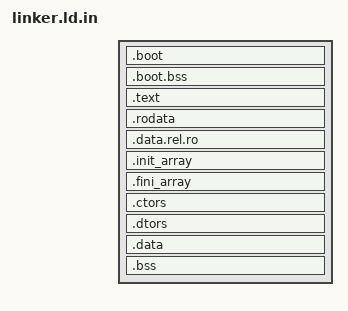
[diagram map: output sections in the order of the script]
/*
 * config/linker.ld.in
 *
 * Preprocessed into build/linker.ld. The addresses come from config/layout.h, which the early
 * boot assembly includes as well, so the two cannot drift apart.
 */

#include "config/layout.h"

ENTRY(_start32)

KERNEL_LMA = DOOM_OS_KERNEL_LMA;
KERNEL_VMA = DOOM_OS_KERNEL_VMA;

/*
 * Both sides take this from config/layout.h now, so they agree by construction - but a stale
 * build/linker.ld would not, and a kernel linked at one address and mapped at another shows up
 * as a triple fault on the jump to the higher half and nothing else. Cheap to keep checking.
 */
ASSERT(ASM_KERNEL_VMA == KERNEL_VMA,
       "KERNEL_VMA disagrees between config/linker.ld and kernel/boot/longmode.S")

PF_X = 0x1;
PF_W = 0x2;
PF_R = 0x4;

PHDRS
{
    /*
     * FILEHDR PHDRS makes the first PT_LOAD segment include the ELF header
     * and program headers. This prevents the first loadable section from
     * being pushed too far into the file.
     */
    boot   PT_LOAD FILEHDR PHDRS FLAGS(PF_R | PF_W | PF_X);
    text   PT_LOAD FLAGS(PF_R | PF_X);
    rodata PT_LOAD FLAGS(PF_R);
    data   PT_LOAD FLAGS(PF_R | PF_W);
}

SECTIONS
{
    /*
     * Start after the ELF/program headers inside the first PT_LOAD segment.
     * The Multiboot2 header below must still appear within the first 32 KiB
     * of the final kernel image.
     */
    . = KERNEL_LMA + SIZEOF_HEADERS;

    boot_start = .;

    .boot ALIGN(8) : AT(ADDR(.boot))
    {
        . = ALIGN(8);

        /*
         * GRUB requires the full Multiboot2 header to be 8-byte aligned and
         * fully contained within the first 32 KiB of the image.
         */
        KEEP(*(.multiboot2_header))
        KEEP(*(.multiboot2))
        KEEP(*(.multiboot))

        *(.boot.text .boot.text.*)
        *(.boot.rodata .boot.rodata.*)
        *(.boot.data .boot.data.*)
    } :boot

    .boot.bss ALIGN(4K) (NOLOAD) : AT(ADDR(.boot.bss))
    {
        boot_bss_start = .;
        *(.boot.bss .boot.bss.*)
        boot_bss_end = .;
    } :boot

    . = ALIGN(4K);
    boot_end = .;

    . = KERNEL_VMA + boot_end;

    kernel_start = .;

    .text ALIGN(4K) : AT(ADDR(.text) - KERNEL_VMA)
    {
        __text_start = .;
        *(.text .text.*)
        *(.gnu.linkonce.t.*)
        __text_end = .;
    } :text

    .rodata ALIGN(4K) : AT(ADDR(.rodata) - KERNEL_VMA)
    {
        __rodata_start = .;
        *(.rodata .rodata.*)
        *(.gnu.linkonce.r.*)
        __rodata_end = .;
    } :rodata

    /*
     * Keep these writable for now.
     * They are often logically read-only after relocation/init,
     * but for a freestanding kernel bring-up it is safer not to
     * make them R-only yet.
     */
    .data.rel.ro ALIGN(4K) : AT(ADDR(.data.rel.ro) - KERNEL_VMA)
    {
        __data_rel_ro_start = .;
        *(.data.rel.ro .data.rel.ro.*)
        *(.data.rel.ro.local .data.rel.ro.local.*)
        __data_rel_ro_end = .;
    } :data

    .init_array ALIGN(8) : AT(ADDR(.init_array) - KERNEL_VMA)
    {
        __init_array_start = .;
        KEEP(*(SORT_BY_INIT_PRIORITY(.init_array.*)))
        KEEP(*(.init_array))
        __init_array_end = .;
    } :data

    .fini_array ALIGN(8) : AT(ADDR(.fini_array) - KERNEL_VMA)
    {
        __fini_array_start = .;
        KEEP(*(SORT_BY_INIT_PRIORITY(.fini_array.*)))
        KEEP(*(.fini_array))
        __fini_array_end = .;
    } :data

    /* GCC emits global constructors into either .init_array or the legacy .ctors, and which one
       is decided when GCC itself is configured, not by any flag we can pass here. A cross GCC
       built --without-headers cannot run the configure probe that selects .init_array, so it
       falls back to .ctors unless it was built --enable-initfini-array.
       kernel/runtime/init.cpp walks .init_array. Collecting .ctors here and asserting it empty is what
       stops a toolchain of the wrong kind from silently dropping every constructor in the image
       into an orphan section nothing ever calls. */
    .ctors ALIGN(8) : AT(ADDR(.ctors) - KERNEL_VMA)
    {
        __ctors_start = .;
        KEEP(*(SORT_BY_NAME(.ctors.*)))
        KEEP(*(.ctors))
        __ctors_end = .;
    } :data

    .dtors ALIGN(8) : AT(ADDR(.dtors) - KERNEL_VMA)
    {
        __dtors_start = .;
        KEEP(*(SORT_BY_NAME(.dtors.*)))
        KEEP(*(.dtors))
        __dtors_end = .;
    } :data

    ASSERT(__ctors_end == __ctors_start,
           "This toolchain emits .ctors instead of .init_array, so global constructors would \
never run. Rebuild the toolchain image with --enable-initfini-array.")

    ASSERT(__dtors_end == __dtors_start,
           "This toolchain emits .dtors instead of .fini_array.")

    .data ALIGN(4K) : AT(ADDR(.data) - KERNEL_VMA)
    {
        __data_start = .;
        *(.data .data.*)
        *(.gnu.linkonce.d.*)

        *(.got .got.*)
        *(.got.plt .got.plt.*)
        __data_end = .;
    } :data

    .bss ALIGN(4K) : AT(ADDR(.bss) - KERNEL_VMA)
    {
        __bss_start = .;

        *(COMMON)
        *(.bss .bss.*)
        *(.gnu.linkonce.b.*)

        __bss_end = .;
    } :data

    . = ALIGN(4K);
    kernel_end = .;

    kernel_physical_start = kernel_start - KERNEL_VMA;
    kernel_physical_end = kernel_end - KERNEL_VMA;

    /*
     * The early page tables cover DOOM_OS_EARLY_MAP_SIZE from zero and from KERNEL_VMA. A
     * kernel that outgrew that would link cleanly and fault the moment it touched anything
     * past the mapping.
     */
    ASSERT(kernel_physical_end <= DOOM_OS_EARLY_MAP_SIZE,
           "kernel image does not fit in the early page tables; raise DOOM_OS_EARLY_MAP_SIZE")

    /DISCARD/ :
    {
        *(.eh_frame)
        *(.eh_frame_hdr)
        *(.comment)
        *(.note .note.*)
        *(.note.GNU-stack)
    }
}
